# TESTCHIP register map
Registers are access not given, no defined reset value unless marked. A register's access mark holds for its fields unless they carry their own. Offsets are from the block's base; lines under a group give offsets from that group; [hi:lo] are bit positions; {n}, {i} and the like mark numbered series; 'fields as' and 'values as' point back to an identical list; <NAME> marks a mode.

## Memory map
0x40012000 ADC1
0x40012100 ADC2
0x40026400 DMA2

## ADC1
Base 0x40012000
Same registers: ADC2 0x40012100
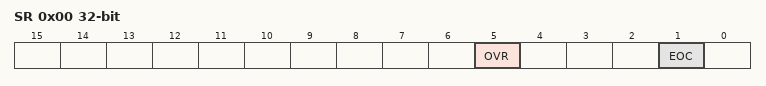
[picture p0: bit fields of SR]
0x00 SR
  [5] OVR, [1] EOC
0x4C DR read-clears

## DMA2
Base 0x40026400
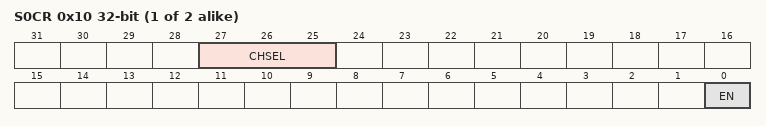
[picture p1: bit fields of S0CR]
{0x10+0x18*i} S{i}CR (i=0..1)
  [27:25] CHSEL, [0] EN
{0x14+0x18*i} S{i}NDTR (i=0..1)
